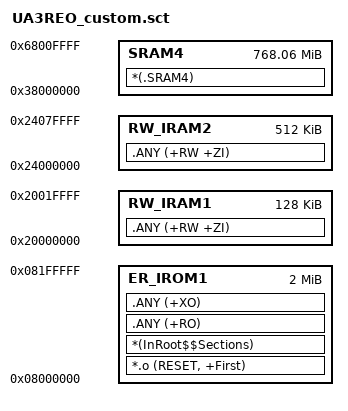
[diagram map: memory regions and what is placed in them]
; *************************************************************
; *** Scatter-Loading Description File generated by uVision ***
; *************************************************************

LR_IROM1 0x08000000 0x00200000  {    ; load region size_region
  ER_IROM1 0x08000000 0x00200000  {  ; load address = execution address
   *.o (RESET, +First)
   *(InRoot$$Sections)
   .ANY (+RO)
   .ANY (+XO)
  }
  RW_IRAM1 0x20000000 0x00020000  {  ; RW data
   .ANY (+RW +ZI)
  }
  RW_IRAM2 0x24000000 0x00080000  {
   .ANY (+RW +ZI)
  }
  ;SRAM1 0x30000000 0x30020000  {
  ; *(.SRAM1)
  ;}
  ;SRAM2 0x30020000 0x30040000  {
  ; *(.SRAM2)
  ;}
  ;SRAM3 0x30040000 0x30050000  {
  ; *(.SRAM3)
  ;}
  SRAM4 0x38000000 0x30010000  {
   *(.SRAM4)
  }
}

